# MDR1206AFI register map
Vendor: Milandr; File version: 2.0
CPU: BM-310S0, little endian
Registers are 32-bit, read-write, reset 0x0 unless marked. A register's access mark holds for its fields unless they carry their own. Offsets are from the block's base; [hi:lo] are bit positions; lines under a group give offsets from that group; {n}, {i} and the like mark numbered series.

## WWDG
Base 0x50048000
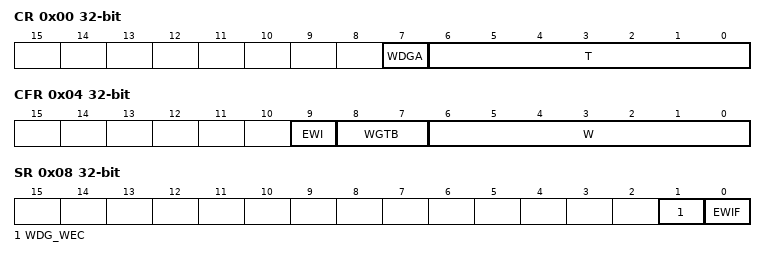
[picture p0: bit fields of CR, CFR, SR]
0x00 CR — WWDG Control Register
  [7] WDGA — WWDG Activation Bit
  [6:0] T — The value of the 7-bit counter
0x04 CFR — WWDG Configuration Register
  [9] EWI — Early Wakeup Interrupt
  [8:7] WGTB — Watchdog Timer frequency divisor
    0=(WDG_CLK/4096)/1; 1=(WDG_CLK/4096)/2; 2=(WDG_CLK/4096)/4; 3=(WDG_CLK/4096)/8
  [6:0] W — Window-value
0x08 SR — WWDG Status Register
  [1] WDG_WEC — Signals that writing into WDG_WEC WWDG_CR and WWDG_CFR has been completed
  [0] EWIF — Early Wakeup Interrupt Flag

## IWDG — IWDG Controller
Base 0x50050000
0x00 KR — IWDG Key Register
  [15:0] KEY — Key value
0x04 PR — IWDG Prescaler Register
  [2:0] PR — Prescaler
    0=LSI_4; 1=LSI_8; 2=LSI_16; 3=LSI_32; 5=LSI_128; 6=LSI_256; 7=LSI_256_EXTRA
0x08 RLR — IWDG Reload Register
  [11:0] RLR — Reload Value Register
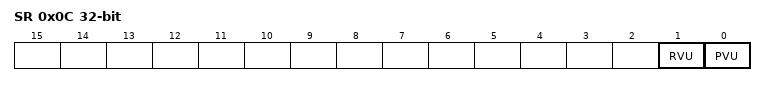
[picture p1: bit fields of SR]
0x0C SR — IWDG Status Register
  [1] RVU — IWDG counter reload value update
  [0] PVU — IWDG prescaler value update

## POWER — Power Detector
Base 0x50058000
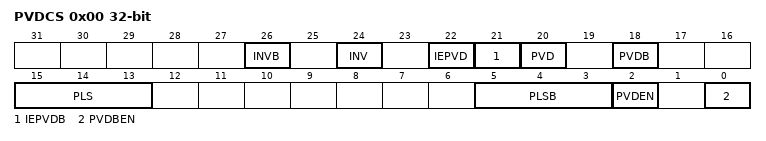
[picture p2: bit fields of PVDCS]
0x00 PVDCS — Power Detector Control and Status Register
  [26] INVB — Inversion of PVDB
  [24] INV — Inversion of PVD
  [22] IEPVD — PVD Interrupt Flag
  [21] IEPVDB — PVDB Interrupt Flag
  [20] PVD — The result of the comparison for Ucc
    0=Ucc_less (Ucc is less than PLS value); 1=Ucc_esc (Ucc exceeds PLS value)
  [18] PVDB — The result of the comparison for UccB
    0=UccB_less (UccB is less than the PLSB value); 1=UccB exceeds the PLSB value
  [15:13] PLS — Selects Ucc comparison value
    0=greater than 2.3V; 1=greater than 2.4V; 2=greater than 2.5V; 3=greater than 2.6V; 4=greater than 2.7V; 5=greater than 2.8V; 6=greater than 2.9V; 7=greater than 3.0V
  [5:3] PLSB — Selects UccB comparison value
    0=greater than 1.8V; 1=greater than 2.0V; 2=greater than 2.2V; 3=greater than 2.4V; 4=greater than 2.6V; 5=greater than 2.8V; 6=greater than 3.0V; 7=greater than 3.2V
  [2] PVDEN — Enables Ucc and OverVoltage PVD
  [0] PVDBEN — Enables Battery PVD

## PORTA — PORTA controller
Base 0x50080000
Same registers: PORTB 0x50088000, PORTC 0x50090000, PORTD 0x500F0000
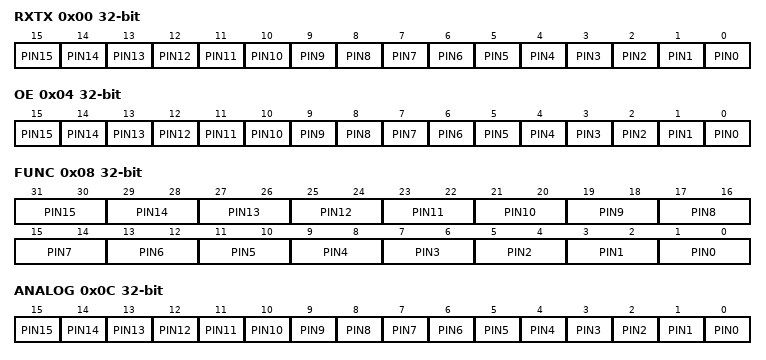
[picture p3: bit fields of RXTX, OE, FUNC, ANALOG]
0x00 RXTX — Direct access to the port data. When read a user gets the data of the receiver. ANALOG_EN=0:0, ANALOG_EN=1: output state. When write - the data are written in the output data register of the transmitter
  [n] PIN{n} (n=0..15)
0x04 OE — Operating mode of the transmitter. 0 - Off. Analog mode, 1 - On. Digital mode
  [n] PIN{n} (n=0..15)
0x08 FUNC — Function register
  [all] fields
    0=IO_Port; 1=Main; 2=Alternative; 3=Overridden
  [2n+1:2n] PIN{n} (n=0..15)
0x0C ANALOG — Operating mode of the receiver. 0 - Receiver is disabled. Analog mode, 1 - Receiver is enabled. Digital mode
  [n] PIN{n} (n=0..15)
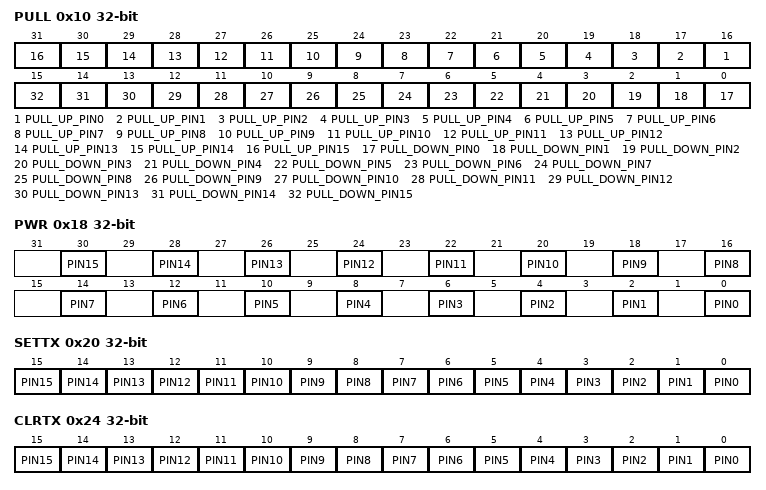
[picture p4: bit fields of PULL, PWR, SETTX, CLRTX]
0x10 PULL — Pull-up/pull-down register
  [n+16] PULL_UP_PIN{n} (n=0..15), [n] PULL_DOWN_PIN{n} (n=0..15)
0x18 PWR — Power of the transmitter
  [all] fields
    0=Enhanced (4 mA load); 1=Nominal (2 mA load)
  [2n] PIN{n} (n=0..15)
0x20 SETTX — Register sets the output data of the port transmitter
  [n] PIN{n} (n=0..15)
0x24 CLRTX — Register clears the output data of the port transmitter
  [n] PIN{n} (n=0..15)
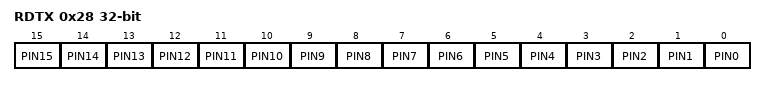
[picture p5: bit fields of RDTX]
0x28 RDTX ro — Output data of the port transmitter
  [n] PIN{n} (n=0..15)

## CRC — CRC Controller
Base 0x50098000
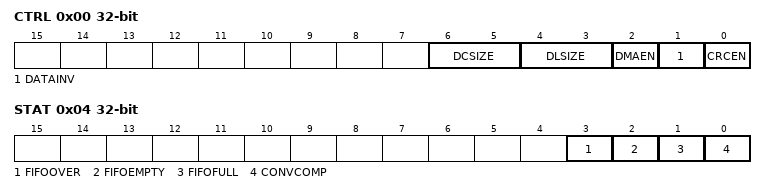
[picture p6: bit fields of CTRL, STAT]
0x00 CTRL — Control Register
  [6:5] DCSIZE — Data size for CRC calculation
    0=Calc_Byte (Calculation is fulfilled for a byte. DLSize=00,01,10); 1=Calc_Halfword (Calculation is fulfilled for a byte. DLSize=01,10); 2=Calc_Word (Calculation is fulfilled for a byte. DLSize=10 only)
  [4:3] DLSIZE — The size of the loaded data
    0=Byte (which is written in CRC_DATAI[7:0]); 1=Halfword (which is written in CRC_DATAI[15:0]); 2=Word (which is written in CRC_DATAI[31:0])
  [2] DMAEN — Enables request to DMA
  [1] DATAINV — Sequence order of CRC calculation
    0=Least_signif_bit; 1=Most_signif_bit
  [0] CRCEN — Enables the CRC controller
0x04 STAT — Status Register
  [3] FIFOOVER — FIFO overflow
    0=OK (Correct operation); 1=Lost (A write into the full FIFO has led to the data loss)
  [2] FIFOEMPTY — FIFO state
    0=Not_Empty (FIFO has at least one written bit); 1=Empty (FIFO is empty)
  [1] FIFOFULL — FIFO state
    0=Not_Full (FIFO has at least one empty bit); 1=Full (FIFO is full)
  [0] CONVCOMP — CRC Status
    0=Calc_On (Calculation is being performed); 1=Calc_Off (Calculation is fulfilled or the CRC controller is disabled)
0x08 DATAI wo — Register for writing a new sample into FIFO
  [31:0] DATA_IN — DATA for a new FIFO sample
0x0C VAL — Calculated CRC Value Register
  [15:0] CRCOUT — Calculated or initial value. Write an initial value when the CRC controller is disabled or the calculation has been finished
0x10 POL — Polynomial for CRC
  [16:0] CRC_POL — 16-bit CRC. The least and the most significant bits are always "1" and cannot be changed

## RANDOM — Random Number Generator
Base 0x500B8000
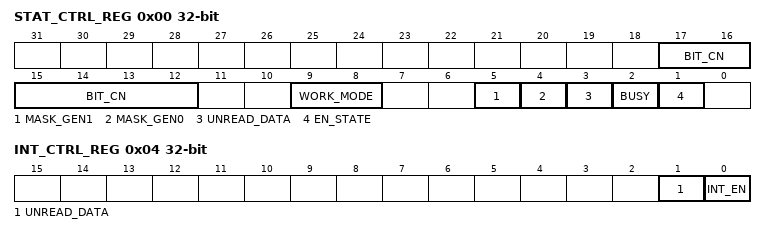
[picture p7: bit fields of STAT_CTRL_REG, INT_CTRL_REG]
0x00 STAT_CTRL_REG — Status and Control Register
  [17:12] BIT_CN ro — The counter of the bits which are left till the beginning of a new gathering
  [9:8] WORK_MODE — Gathering of a random number
    0=Halt_Gathering; 1=Single; 2=Start on Read (when UNREAD_DATA=0); 3=Continuous
  [5] MASK_GEN1 — Selects Gen1
  [4] MASK_GEN0 — Selects Gen0
  [3] UNREAD_DATA ro — There are unread data
  [2] BUSY ro — The generator is busy gathering a random value
  [1] EN_STATE ro — There is a least one group of enabled generators and the PAUSE is finished
0x04 INT_CTRL_REG — Interrupt Control Register
  [1] UNREAD_DATA ro — There are unread data
  [0] INT_EN — Enables the interrupt
0x08 CLK_DIV_REG — Clock Divider Register
  [15:0] DIV — RANDOM_CLK/(2*(DIV+1))
0x0C PAUSE_REG — Pause Register
0x10 OUTPUT_REG ro — The last random number
0x14 PAUSE_CNT_REG ro — Pause Counter Register
0x18 TEMP_REG ro — The current value of the shift register for a random number

## USART — USART ISO 7816
Base 0x500C0000
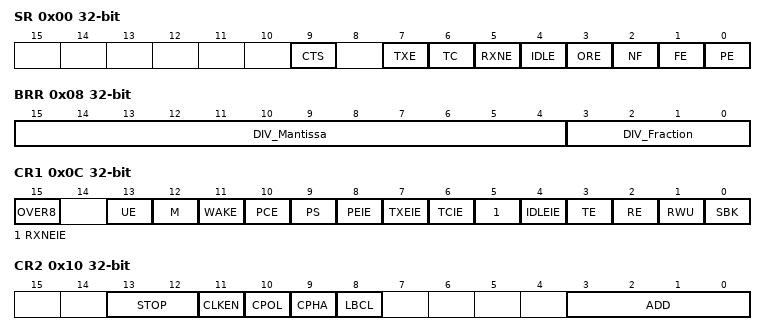
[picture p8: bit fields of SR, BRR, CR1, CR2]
0x00 SR — Status Register
  [9] CTS — CTS flag
  [7] TXE ro — TX empty
  [6] TC — Transmit complete
  [5] RXNE — Read data register not empty
  [4] IDLE ro — IDLE line detected
  [3] ORE ro — Overrun error
  [2] NF ro — Noise error flag
  [1] FE ro — Frame error
  [0] PE ro — Parity error
0x04 DR — Data Register
  [8:0] DR
0x08 BRR — Baud Rate Register
  [15:4] DIV_Mantissa, [3:0] DIV_Fraction
0x0C CR1 — Control Register 1
  [15] OVER8 — Oversampling mode
    0=OS_16 (Oversampling by 16); 1=OS_8 (Oversampling by 8. OS_8 is not available in the smartcard mode)
  [13] UE — USART Enable
  [12] M — Word length
    0=L_8 (1 start bit, 8 data bits, n stop bit); 1=L_9 (1 start bit, 9 data bits, n stop bit)
  [11] WAKE — USART wake up method
    0=IDLE (the waiting state); 1=Address_mark
  [10] PCE — Enables parity control
  [9] PS — Parity selection
    0=Evenness_Control; 1=Oddness_Control
  [8] PEIE — Enables the interrupt on PE
    0=No_Int; 1=Int_En (When PE=1 in the USART_SR)
  [7] TXEIE — Enables TXE interrupt
    0=No_Int; 1=Int_En (When TXE=1 in the USART_SR)
  [6] TCIE — Enables interrupt when transmission has been completed
    0=No_Int; 1=Int_En (When TC=1 in the USART_SR)
  [5] RXNEIE — Enables RXNE interrupt
    0=No_Int; 1=Int_En (When ORE=1 or RXNE=1 in the USART_SR)
  [4] IDLEIE — Enables IDLE interrupt
    0=No_Int; 1=Int_En (When IDLE=1 in the USART_SR)
  [3] TE — Enables the transmitter
  [2] RE — Enables the receiver
  [1] RWU — Receiver wakeup
  [0] SBK — Send break
    0=No_BK; 1=BK_Sent (The BK is transmitted)
0x10 CR2 — Control Register 2
  [13:12] STOP — Stop bit type mask
  [11] CLKEN — Clock enable
  [10] CPOL — Clock polarity
  [9] CPHA — Clock phase
  [8] LBCL — Last bit clock pulse
  [3:0] ADD — Address of the USART node
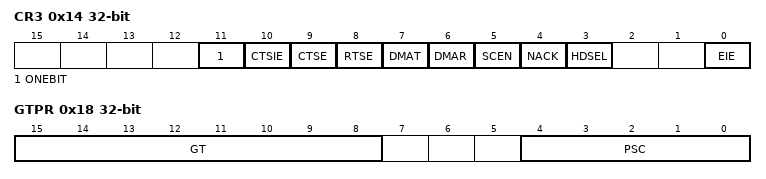
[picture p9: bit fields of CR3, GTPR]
0x14 CR3 — Control Register 3
  [11] ONEBIT — The method of digitization. Don't use for a start bit
    0=One_S (Three samles per bit); 1=Three_S (One sample per bit)
  [10] CTSIE — CTS interrupt enable
    0=No_Int (The interrupt is disabled); 1=Int_En (when CTS=1 in the USATY_SR Register)
  [9] CTSE — Enables CTS
  [8] RTSE — RTS enable
  [7] DMAT — Enables DMA transmitter
  [6] DMAR — Enables DMA receiver
  [5] SCEN — Enables smartcard mode
  [4] NACK — Enables NACK in the smartcard mode
  [3] HDSEL — Half-duplex selection
  [0] EIE — Error interrupt enable
    0=No_Int (The interrupt is disabled); 1=Int_En (when DMAR=1 in USART_CR3 and FE=1)
0x18 GTPR — Guard Time and Prescaler Register
  [15:8] GT — Guard time in cycles
  [4:0] PSC — Prescaler value in the smartcard mode
